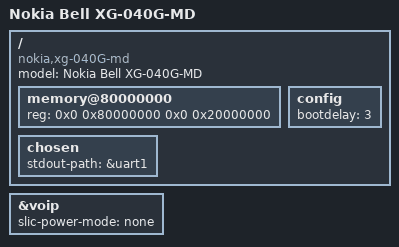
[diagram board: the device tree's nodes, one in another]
#include <dt-bindings/interrupt-controller/irq.h>
#include <dt-bindings/interrupt-controller/arm-gic.h>
#include <dt-bindings/gpio/gpio.h>
#include <dt-bindings/leds/common.h>
#include <dt-bindings/input/input.h>

/dts-v1/;

#include "en7581-base.dtsi"

/ {
	model = "Nokia Bell XG-040G-MD";
    compatible = "nokia,xg-040G-md", "econet,en7581-eagle", "econet,en7581", "airoha,en7581";

    memory@80000000 {
        reg = <0x0 0x80000000 0x0 0x20000000>;  // 512 MiB
    };

    chosen {
        stdout-path = &uart1;
    };

	config {
		bootdelay = <3>;
	};
};

&voip {
	slic-power-mode = "none";
};

